# STM32G474xx register map
File version: 1.5
CPU: CM4 r0p1, little endian, MPU, FPU, 4 interrupt priority bits
Registers are 32-bit, read-write, reset 0x0 unless marked. A register's access mark holds for its fields unless they carry their own. Offsets are from the block's base; [hi:lo] are bit positions; {n}, {i} and the like mark numbered series; 'fields as' and 'values as' point back to an identical list.

## FMC — Flexible memory controller
Base 0xA0000000
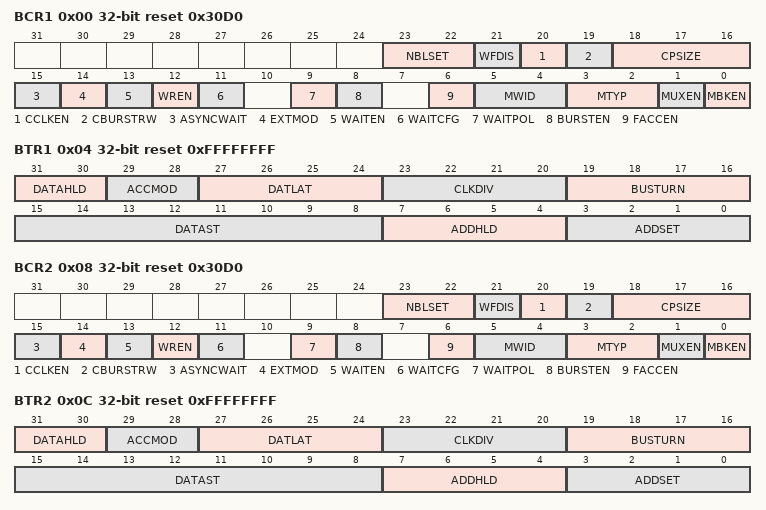
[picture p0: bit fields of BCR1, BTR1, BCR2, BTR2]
0x00 BCR1 reset 0x30D0 — SRAM/NOR-Flash chip-select control register 1
  [23:22] NBLSET, [21] WFDIS, [20] CCLKEN, [19] CBURSTRW, [18:16] CPSIZE, [15] ASYNCWAIT, [14] EXTMOD, [13] WAITEN, [12] WREN, [11] WAITCFG, [9] WAITPOL, [8] BURSTEN, [6] FACCEN, [5:4] MWID, [3:2] MTYP, [1] MUXEN, [0] MBKEN
0x04 BTR1 reset 0xFFFFFFFF — SRAM/NOR-Flash chip-select timing register 1
  [31:30] DATAHLD, [29:28] ACCMOD, [27:24] DATLAT, [23:20] CLKDIV, [19:16] BUSTURN, [15:8] DATAST, [7:4] ADDHLD, [3:0] ADDSET
0x08 BCR2 reset 0x30D0 — SRAM/NOR-Flash chip-select control register 2
  fields as BCR1
0x0C BTR2 reset 0xFFFFFFFF — SRAM/NOR-Flash chip-select timing register 2
  fields as BTR1
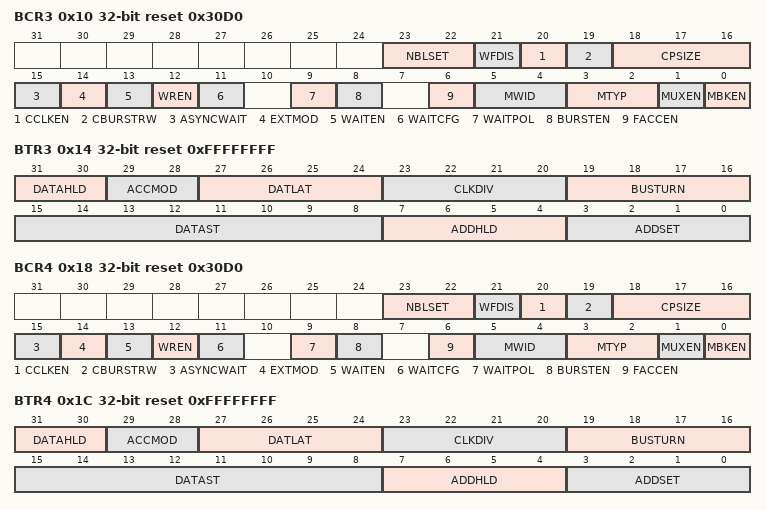
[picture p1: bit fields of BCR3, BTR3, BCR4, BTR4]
0x10 BCR3 reset 0x30D0 — SRAM/NOR-Flash chip-select control register 3
  fields as BCR1
0x14 BTR3 reset 0xFFFFFFFF — SRAM/NOR-Flash chip-select timing register 3
  fields as BTR1
0x18 BCR4 reset 0x30D0 — SRAM/NOR-Flash chip-select control register 4
  fields as BCR1
0x1C BTR4 reset 0xFFFFFFFF — SRAM/NOR-Flash chip-select timing register 4
  fields as BTR1
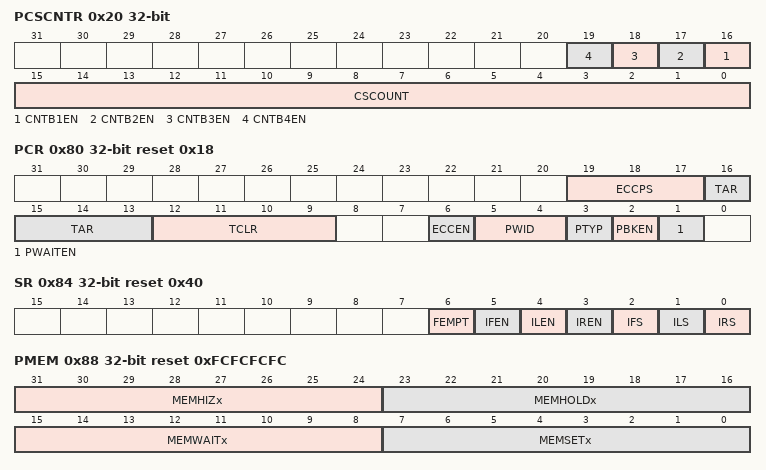
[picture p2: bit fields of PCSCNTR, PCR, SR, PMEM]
0x20 PCSCNTR — PSRAM chip select counter register
  [n+15] CNTB{n}EN (n=1..4), [15:0] CSCOUNT
0x80 PCR reset 0x18 — PC Card/NAND Flash control register 3
  [19:17] ECCPS, [16:13] TAR, [12:9] TCLR, [6] ECCEN, [5:4] PWID, [3] PTYP, [2] PBKEN, [1] PWAITEN
0x84 SR access per field reset 0x40 — FIFO status and interrupt register 3
  [6] FEMPT ro, [5] IFEN rw, [4] ILEN rw, [3] IREN rw, [2] IFS rw, [1] ILS rw, [0] IRS rw
0x88 PMEM reset 0xFCFCFCFC — Common memory space timing register 3
  [31:24] MEMHIZx, [23:16] MEMHOLDx, [15:8] MEMWAITx, [7:0] MEMSETx
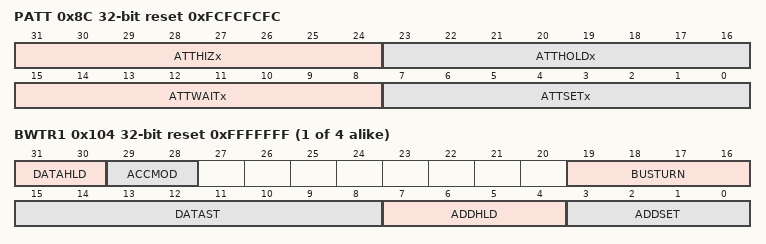
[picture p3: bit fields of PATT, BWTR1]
0x8C PATT reset 0xFCFCFCFC — Attribute memory space timing register 3
  [31:24] ATTHIZx, [23:16] ATTHOLDx, [15:8] ATTWAITx, [7:0] ATTSETx
0x94 ECCR ro — ECC result register 3
  [31:0] ECCx
{0xFC+8i} BWTR{i} reset 0xFFFFFFF (i=1..4) — SRAM/NOR-Flash write timing registers {i}
  [31:30] DATAHLD, [29:28] ACCMOD, [19:16] BUSTURN, [15:8] DATAST, [7:4] ADDHLD, [3:0] ADDSET

## DMA1 — DMA controller
Base 0x40020000
Same registers: DMA2 0x40020400
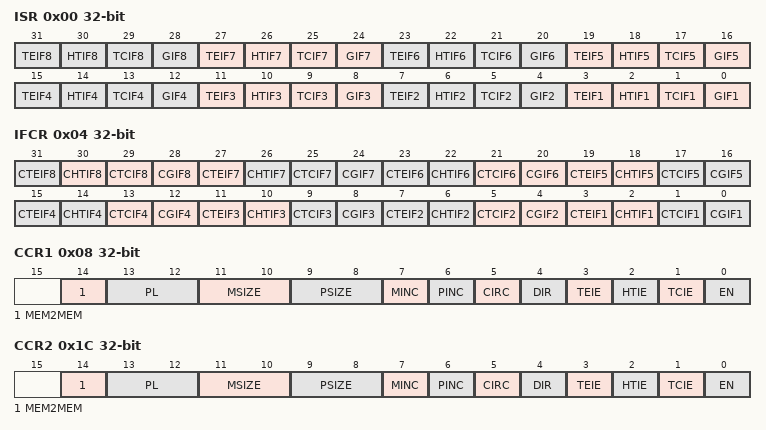
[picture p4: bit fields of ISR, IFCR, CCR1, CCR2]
0x00 ISR ro — interrupt status register
  [4n-1] TEIF{n} (n=1..8), [4n-2] HTIF{n} (n=1..8), [4n-3] TCIF{n} (n=1..8), [4n-4] GIF{n} (n=1..8)
0x04 IFCR wo — DMA interrupt flag clear register
  [4n-1] CTEIF{n} (n=1..8)
  [30] CHTIF8
  [4n-3] CTCIF{n} (n=1..8)
  [4n-4] CGIF{n} (n=1..8)
  [26] CHTIF7 — HTIF7
  [4n-2] CHTIF{n} (n=1..6)
0x08 CCR1 — DMA channel 1 configuration register
  [14] MEM2MEM
  [13:12] PL
  [11:10] MSIZE
  [9:8] PSIZE
  [7] MINC
  [6] PINC
  [5] CIRC
  [4] DIR
  [3] TEIE
  [2] HTIE
  [1] TCIE
  [0] EN — channel enable
0x0C CNDTR1 — channel x number of data to transfer register
  [15:0] NDT — Number of data items to transfer
0x10 CPAR1 — DMA channel x peripheral address register
  [31:0] PA — Peripheral address
{0x0+0x14*i} CMAR{i} (i=1..8) — DMA channel x memory address register
  [31:0] MA — Memory 1 address (used in case of Double buffer mode)
0x1C CCR2 — DMA channel 2 configuration register
  fields as CCR1
0x20 CNDTR2 — channel x number of data to transfer register
  [15:0] NDT — Number of data items to transfer
0x24 CPAR2 — DMA channel x peripheral address register
  [31:0] PA — Peripheral address
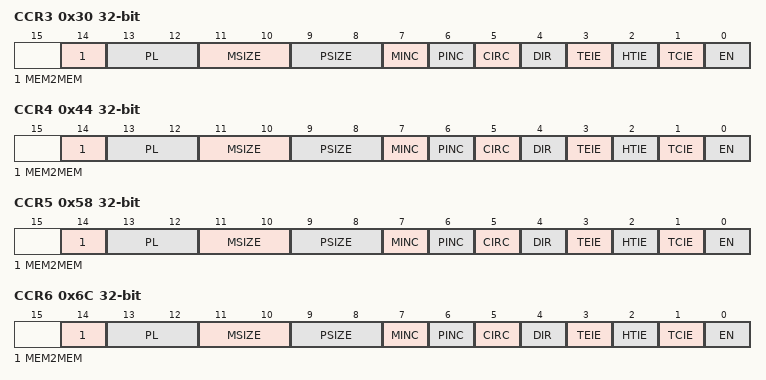
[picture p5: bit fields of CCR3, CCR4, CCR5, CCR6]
0x30 CCR3 — DMA channel 3 configuration register
  fields as CCR1
0x34 CNDTR3 — channel x number of data to transfer register
  [15:0] NDT — Number of data items to transfer
0x38 CPAR3 — DMA channel x peripheral address register
  [31:0] PA — Peripheral address
0x44 CCR4 — DMA channel 3 configuration register
  fields as CCR1
0x48 CNDTR4 — channel x number of data to transfer register
  [15:0] NDT — Number of data items to transfer
0x4C CPAR4 — DMA channel x peripheral address register
  [31:0] PA — Peripheral address
0x58 CCR5 — DMA channel 4 configuration register
  fields as CCR1
0x5C CNDTR5 — channel x number of data to transfer register
  [15:0] NDT — Number of data items to transfer
0x60 CPAR5 — DMA channel x peripheral address register
  [31:0] PA — Peripheral address
0x6C CCR6 — DMA channel 5 configuration register
  fields as CCR1
0x70 CNDTR6 — channel x number of data to transfer register
  [15:0] NDT — Number of data items to transfer
0x74 CPAR6 — DMA channel x peripheral address register
  [31:0] PA — Peripheral address
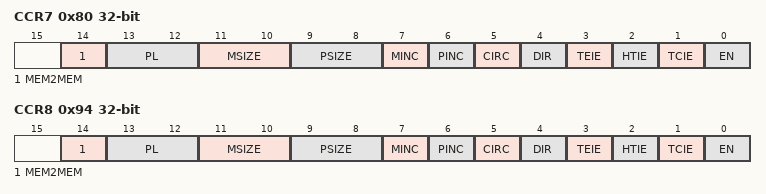
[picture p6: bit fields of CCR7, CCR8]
0x80 CCR7 — DMA channel 6 configuration register
  fields as CCR1
0x84 CNDTR7 — channel x number of data to transfer register
  [15:0] NDT — Number of data items to transfer
0x88 CPAR7 — DMA channel x peripheral address register
  [31:0] PA — Peripheral address
0x94 CCR8 — DMA channel 7 configuration register
  fields as CCR1
0x98 CNDTR8 — channel x number of data to transfer register
  [15:0] NDT — Number of data items to transfer
0x9C CPAR8 — DMA channel x peripheral address register
  [31:0] PA — Peripheral address
